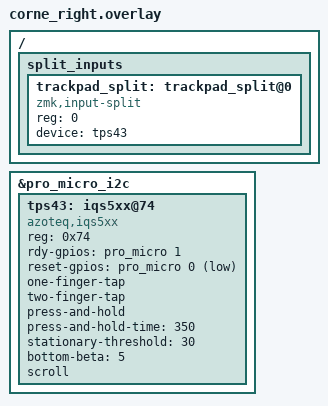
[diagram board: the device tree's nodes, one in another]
#include <dt-bindings/zmk/input_transform.h>

&pro_micro_i2c {
    status = "okay";

    tps43: iqs5xx@74 {
        compatible = "azoteq,iqs5xx";
        reg = <0x74>;
        status = "okay";
        rdy-gpios = <&pro_micro 1 (GPIO_ACTIVE_HIGH)>;
        reset-gpios = <&pro_micro 0 (GPIO_ACTIVE_LOW)>;

        /* Gesture & Feature Configuration */
        one-finger-tap;
        two-finger-tap;
        press-and-hold;
        press-and-hold-time = <350>;
        stationary-threshold = <30>;
        bottom-beta = <5>;
        scroll;
        /* natural-scroll-y; */
        /* natural-scroll-x; */
        /* switch-xy; */
    };
};

/* Peripheral (Right) half: bridges tps43 input events over BLE split link to central */
/ {
    split_inputs {
        #address-cells = <1>;
        #size-cells = <0>;

        trackpad_split: trackpad_split@0 {
            compatible = "zmk,input-split";
            reg = <0>;
            device = <&tps43>;
        };
    };
};
